AUTOSAR XML (schema 4-0-3)
package /ComponentTypes
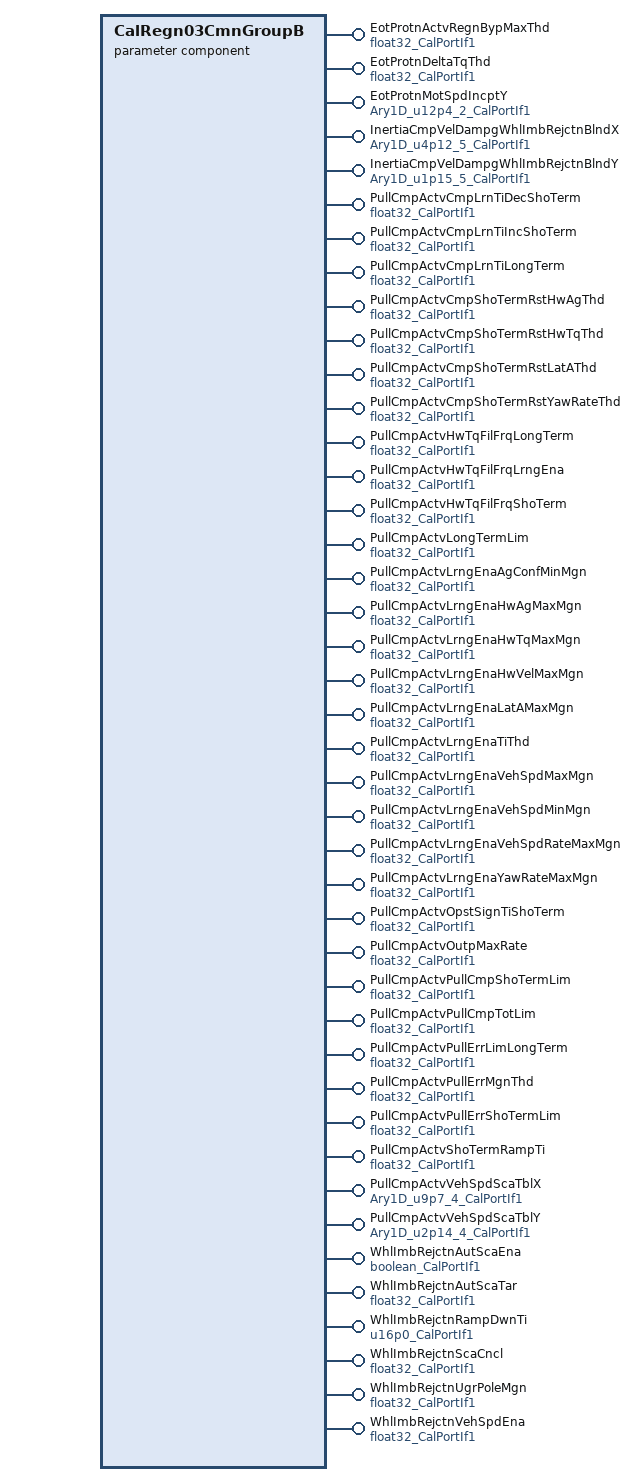
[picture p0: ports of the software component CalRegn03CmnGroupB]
  parameter sw component type CalRegn03CmnGroupB
    42 x provide port:
      EotProtnActvRegnBypMaxThd: parameter-provide-com-spec{init-value=0.5, parameter=Val}, provided-interface=float32_CalPortIf1
      EotProtnDeltaTqThd: parameter-provide-com-spec{init-value=0, parameter=Val}, provided-interface=float32_CalPortIf1
      EotProtnMotSpdIncptY: parameter-provide-com-spec{init-value=[10400, 10400], parameter=Ary1D}, provided-interface=Ary1D_u12p4_2_CalPortIf1
      InertiaCmpVelDampgWhlImbRejctnBlndX: parameter-provide-com-spec{init-value=[208, 432, 640, 848, 1056], parameter=Ary1D}, provided-interface=Ary1D_u4p12_5_CalPortIf1
      InertiaCmpVelDampgWhlImbRejctnBlndY: parameter-provide-com-spec{init-value=5 x 0, parameter=Ary1D}, provided-interface=Ary1D_u1p15_5_CalPortIf1
      PullCmpActvCmpLrnTiDecShoTerm: parameter-provide-com-spec{init-value=45, parameter=Val}, provided-interface=float32_CalPortIf1
      PullCmpActvCmpLrnTiIncShoTerm: parameter-provide-com-spec{init-value=45, parameter=Val}, provided-interface=float32_CalPortIf1
      PullCmpActvCmpLrnTiLongTerm: parameter-provide-com-spec{init-value=45, parameter=Val}, provided-interface=float32_CalPortIf1
      PullCmpActvCmpShoTermRstHwAgThd: parameter-provide-com-spec{init-value=45, parameter=Val}, provided-interface=float32_CalPortIf1
      PullCmpActvCmpShoTermRstHwTqThd: parameter-provide-com-spec{init-value=3, parameter=Val}, provided-interface=float32_CalPortIf1
      PullCmpActvCmpShoTermRstLatAThd: parameter-provide-com-spec{init-value=1, parameter=Val}, provided-interface=float32_CalPortIf1
      PullCmpActvCmpShoTermRstYawRateThd: parameter-provide-com-spec{init-value=1, parameter=Val}, provided-interface=float32_CalPortIf1
      PullCmpActvHwTqFilFrqLongTerm: parameter-provide-com-spec{init-value=0.5, parameter=Val}, provided-interface=float32_CalPortIf1
      PullCmpActvHwTqFilFrqLrngEna: parameter-provide-com-spec{init-value=20, parameter=Val}, provided-interface=float32_CalPortIf1
      PullCmpActvHwTqFilFrqShoTerm: parameter-provide-com-spec{init-value=0.5, parameter=Val}, provided-interface=float32_CalPortIf1
      PullCmpActvLongTermLim: parameter-provide-com-spec{init-value=0.5, parameter=Val}, provided-interface=float32_CalPortIf1
      PullCmpActvLrngEnaAgConfMinMgn: parameter-provide-com-spec{init-value=1, parameter=Val}, provided-interface=float32_CalPortIf1
      PullCmpActvLrngEnaHwAgMaxMgn: parameter-provide-com-spec{init-value=45, parameter=Val}, provided-interface=float32_CalPortIf1
      PullCmpActvLrngEnaHwTqMaxMgn: parameter-provide-com-spec{init-value=2.8, parameter=Val}, provided-interface=float32_CalPortIf1
      PullCmpActvLrngEnaHwVelMaxMgn: parameter-provide-com-spec{init-value=10, parameter=Val}, provided-interface=float32_CalPortIf1
      PullCmpActvLrngEnaLatAMaxMgn: parameter-provide-com-spec{init-value=0.5, parameter=Val}, provided-interface=float32_CalPortIf1
      PullCmpActvLrngEnaTiThd: parameter-provide-com-spec{init-value=2, parameter=Val}, provided-interface=float32_CalPortIf1
      PullCmpActvLrngEnaVehSpdMaxMgn: parameter-provide-com-spec{init-value=160, parameter=Val}, provided-interface=float32_CalPortIf1
      PullCmpActvLrngEnaVehSpdMinMgn: parameter-provide-com-spec{init-value=60, parameter=Val}, provided-interface=float32_CalPortIf1
      PullCmpActvLrngEnaVehSpdRateMaxMgn: parameter-provide-com-spec{init-value=1, parameter=Val}, provided-interface=float32_CalPortIf1
      PullCmpActvLrngEnaYawRateMaxMgn: parameter-provide-com-spec{init-value=1, parameter=Val}, provided-interface=float32_CalPortIf1
      PullCmpActvOpstSignTiShoTerm: parameter-provide-com-spec{init-value=0.1, parameter=Val}, provided-interface=float32_CalPortIf1
      PullCmpActvOutpMaxRate: parameter-provide-com-spec{init-value=100, parameter=Val}, provided-interface=float32_CalPortIf1
      PullCmpActvPullCmpShoTermLim: parameter-provide-com-spec{init-value=1, parameter=Val}, provided-interface=float32_CalPortIf1
      PullCmpActvPullCmpTotLim: parameter-provide-com-spec{init-value=0, parameter=Val}, provided-interface=float32_CalPortIf1
      PullCmpActvPullErrLimLongTerm: parameter-provide-com-spec{init-value=3, parameter=Val}, provided-interface=float32_CalPortIf1
      PullCmpActvPullErrMgnThd: parameter-provide-com-spec{init-value=0.25, parameter=Val}, provided-interface=float32_CalPortIf1
      PullCmpActvPullErrShoTermLim: parameter-provide-com-spec{init-value=3, parameter=Val}, provided-interface=float32_CalPortIf1
      PullCmpActvShoTermRampTi: parameter-provide-com-spec{init-value=1, parameter=Val}, provided-interface=float32_CalPortIf1
      PullCmpActvVehSpdScaTblX: parameter-provide-com-spec{init-value=[0, 3840, 7680, 11520], parameter=Ary1D}, provided-interface=Ary1D_u9p7_4_CalPortIf1
      PullCmpActvVehSpdScaTblY: parameter-provide-com-spec{init-value=[0, 4096, 16384, 16384], parameter=Ary1D}, provided-interface=Ary1D_u2p14_4_CalPortIf1
      WhlImbRejctnAutScaEna: parameter-provide-com-spec{init-value=1, parameter=Logl}, provided-interface=boolean_CalPortIf1
      WhlImbRejctnAutScaTar: parameter-provide-com-spec{init-value=0.199219, parameter=Val}, provided-interface=float32_CalPortIf1
      WhlImbRejctnRampDwnTi: parameter-provide-com-spec{init-value=2000, parameter=Val}, provided-interface=u16p0_CalPortIf1
      WhlImbRejctnScaCncl: parameter-provide-com-spec{init-value=0.1, parameter=Val}, provided-interface=float32_CalPortIf1
      WhlImbRejctnUgrPoleMgn: parameter-provide-com-spec{init-value=1, parameter=Val}, provided-interface=float32_CalPortIf1
      WhlImbRejctnVehSpdEna: parameter-provide-com-spec{init-value=0, parameter=Val}, provided-interface=float32_CalPortIf1
